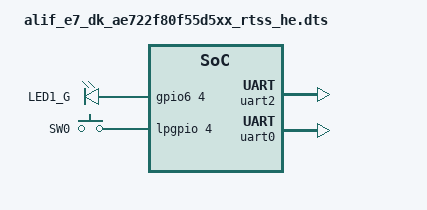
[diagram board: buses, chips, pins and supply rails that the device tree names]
/* Copyright (c) 2025 Alif Semiconductor
 *
 * SPDX-License-Identifier: Apache-2.0
 */

/dts-v1/;

#include <alif/ensemble/e7/ae722f80f55d5xx.dtsi>
#include <alif/ensemble/common/ensemble_rtss_he.dtsi>
#include "../common/ensemble-pinctrl.dtsi"

/ {
	compatible = "arm,alif-e7-dk-ae722f80f55d5xx-rtss-he";
	#address-cells = <1>;
	#size-cells = <1>;

	chosen {
		zephyr,flash = &mram_storage;
		zephyr,code-partition = &slot0_partition;
		zephyr,sram = &dtcm;
		zephyr,console = &uart2;
		zephyr,shell-uart = &uart2;
		zephyr,uart-mcumgr = &uart2;
		zephyr,bt-hci = &bt_hci_uart;
	};

	aliases {
		led0 = &aled0;
                sw0 = &button0;
		watchdog0 = &wdog0;
	};

       leds {
               compatible = "gpio-leds";
               aled0: led_0 {
                       gpios = <&gpio6 4 0>;
                       label = "LED1_G";
               };
       };
       buttons {
               compatible = "gpio-keys";
               button0: button_0 {
                       gpios = < &lpgpio 4 0 >;
                       label = "SW0";
               };
       };
};

&gpio12 {
	status = "okay";
};

&uart2 {
	status = "okay";
};

&ospi1 {
	/* External Flash on OSPI */
	ospi_flash: ospi_flash@0 {
		compatible = "issi,xspi-flash-controller";
		reg = <0x0>;
		erase-value = <0xff>;
		num-of-sector = <16384>;
		page-size = <4096>;
		sector-size = <4096>;
		write-block-size = <2>;

		/* Flash Size 64MB */
		#address-cells = <1>;
		#size-cells = <1>;

		flash_storage: flash_storage@0 {
			compatible = "soc-nv-flash";
			reg = <0x0 DT_SIZE_M(64)>;
			erase-block-size = <DT_SIZE_K(4)>;
			write-block-size = <2>;
		};
	}
	status = "disabled";
}

m2_hci_uart: &uart0 {
	status = "okay";
	hw-flow-control;
	bt_hci_uart: bt_hci_uart {
		compatible = "zephyr,bt-hci-uart";
		status = "okay";
		m2_bt_module {
			compatible = "nxp,bt-hci-uart";
			sdio-reset-gpios = <&gpio12 0 GPIO_ACTIVE_HIGH>;
			w-disable-gpios = <&gpio12 1 GPIO_ACTIVE_HIGH>;
			hci-operation-speed = <115200>;
			hw-flow-control;
			fw-download-primary-speed = <115200>;
			fw-download-primary-flowcontrol;
			//fw-download-secondary-speed = <921600>;
			//fw-download-secondary-flowcontrol;
			status = "okay";
		};
	};
};
